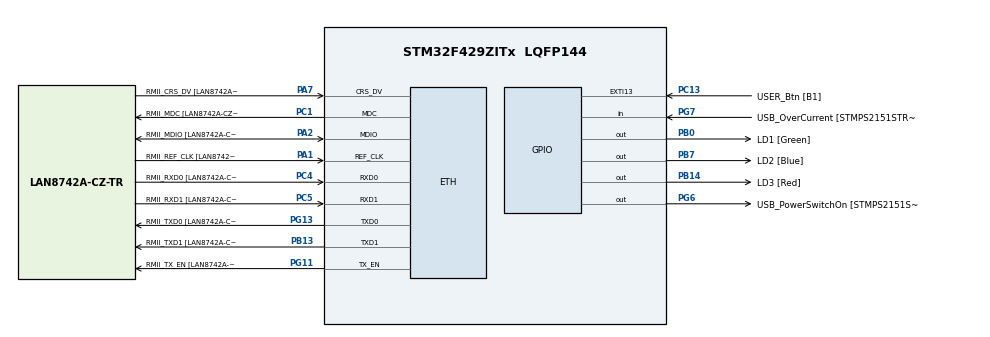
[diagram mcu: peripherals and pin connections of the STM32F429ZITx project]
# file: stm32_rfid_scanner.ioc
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ETH.MediaInterface=HAL_ETH_RMII_MODE
ETH.PHY_Name=LAN8742A_PHY_ADDRESS
ETH.PHY_Value=0
ETH.PhyAddress=0
FREERTOS.Tasks01=defaultTask,0,512,StartDefaultTask,Default,NULL,Dynamic,NULL,NULL;sslTask,0,2560,StartSSLClientTask,As weak,NULL,Dynamic,NULL,NULL;lwipTask,-3,512,handleClientTask,Default,NULL,Dynamic,NULL,NULL
LWIP.BSP.number=1
LWIP.Version=v2.1.2_Cube
LWIP0.BSP.STBoard=false
LWIP0.BSP.api=BSP_COMPONENT_DRIVER
LWIP0.BSP.component=LAN8742
LWIP0.BSP.instance=LAN8742
LWIP0.BSP.name=Driver_PHY
LWIP0.BSP.semaphore=S_LAN8742
LWIP0.BSP.solution=LAN8742
Mcu.Family=STM32F4
Mcu.Name=STM32F429ZITx
Mcu.Package=LQFP144
NVIC.ETH_IRQn=true\:5\:0\:false\:false\:true\:true\:false\:true\:true
NVIC.EXTI15_10_IRQn=true\:5\:0\:false\:false\:true\:true\:true\:true\:true
NVIC.PriorityGroup=NVIC_PRIORITYGROUP_4
PA1.GPIO_Label=RMII_REF_CLK [LAN8742A-CZ-TR_REFCLK0]
PA1.Mode=RMII
PA1.Signal=ETH_REF_CLK
PA10.GPIO_Label=USB_ID
PA10.Signal=USB_OTG_FS_ID
PA11.GPIO_Label=USB_DM
PA11.Signal=USB_OTG_FS_DM
PA12.GPIO_Label=USB_DP
PA12.Signal=USB_OTG_FS_DP
PA13.GPIO_Label=TMS
PA13.Mode=Serial_Wire
PA13.Signal=SYS_JTMS-SWDIO
PA14.GPIO_Label=TCK
PA14.Mode=Serial_Wire
PA14.Signal=SYS_JTCK-SWCLK
PA2.GPIO_Label=RMII_MDIO [LAN8742A-CZ-TR_MDIO]
PA2.Mode=RMII
PA2.Signal=ETH_MDIO
PA7.GPIO_Label=RMII_CRS_DV [LAN8742A-CZ-TR_CRS_DV]
PA7.Mode=RMII
PA7.Signal=ETH_CRS_DV
PA8.GPIO_Label=USB_SOF [TP1]
PA8.Signal=USB_OTG_FS_SOF
PA9.GPIO_Label=USB_VBUS
PA9.Signal=USB_OTG_FS_VBUS
PB0.GPIO_Label=LD1 [Green]
PB0.Signal=GPIO_Output
PB13.GPIO_Label=RMII_TXD1 [LAN8742A-CZ-TR_TXD1]
PB13.Mode=RMII
PB13.Signal=ETH_TXD1
PB14.GPIO_Label=LD3 [Red]
PB14.Signal=GPIO_Output
PB7.GPIO_Label=LD2 [Blue]
PB7.Signal=GPIO_Output
PC1.GPIO_Label=RMII_MDC [LAN8742A-CZ-TR_MDC]
PC1.Mode=RMII
PC1.Signal=ETH_MDC
PC13.GPIO_Label=USER_Btn [B1]
PC13.Signal=GPXTI13
PC14/OSC32_IN.Mode=LSE-External-Oscillator
PC14/OSC32_IN.Signal=RCC_OSC32_IN
PC15/OSC32_OUT.Mode=LSE-External-Oscillator
PC15/OSC32_OUT.Signal=RCC_OSC32_OUT
PC4.GPIO_Label=RMII_RXD0 [LAN8742A-CZ-TR_RXD0]
PC4.Mode=RMII
PC4.Signal=ETH_RXD0
PC5.GPIO_Label=RMII_RXD1 [LAN8742A-CZ-TR_RXD1]
PC5.Mode=RMII
PC5.Signal=ETH_RXD1
PD8.GPIO_Label=STLK_RX [STM32F103CBT6_PA3]
PD8.Signal=USART3_TX
PD9.GPIO_Label=STLK_TX [STM32F103CBT6_PA2]
PD9.Signal=USART3_RX
PG11.GPIO_Label=RMII_TX_EN [LAN8742A-CZ-TR_TXEN]
PG11.Mode=RMII
PG11.Signal=ETH_TX_EN
PG13.GPIO_Label=RMII_TXD0 [LAN8742A-CZ-TR_TXD0]
PG13.Mode=RMII
PG13.Signal=ETH_TXD0
PG6.GPIO_Label=USB_PowerSwitchOn [STMPS2151STR_EN]
PG6.Signal=GPIO_Output
PG7.GPIO_Label=USB_OverCurrent [STMPS2151STR_FAULT]
PG7.Signal=GPIO_Input
PH0/OSC_IN.Mode=HSE-External-Clock-Source
PH0/OSC_IN.Signal=RCC_OSC_IN
PH1/OSC_OUT.Mode=HSE-External-Clock-Source
PH1/OSC_OUT.Signal=RCC_OSC_OUT
ProjectManager.HeapSize=0x200
ProjectManager.StackSize=0x400
ProjectManager.TargetToolchain=STM32CubeIDE
VP_FREERTOS_VS_CMSIS_V1.Mode=CMSIS_V1
VP_LWIP_VS_Enabled.Mode=Enabled
VP_RNG_VS_RNG.Mode=RNG_Activate
board=NUCLEO-F429ZI

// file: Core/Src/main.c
/* USER CODE BEGIN Header */
/**
  ******************************************************************************
  * @file           : main.c
  * @brief          : Main program body
  ******************************************************************************
  * @attention
  *
  * Copyright (c) 2023 STMicroelectronics.
  * All rights reserved.
  *
  * This software is licensed under terms that can be found in the LICENSE file
  * in the root directory of this software component.
  * If no LICENSE file comes with this software, it is provided AS-IS.
  *
  ******************************************************************************
  */
/* USER CODE END Header */
#include "main.h"
#include "cmsis_os.h"
#include "lwip.h"

/* USER CODE BEGIN Includes */
#include "iot_connect.h"
#include "SEGGER_RTT.h"
/* USER CODE END Includes */

RNG_HandleTypeDef hrng;

osThreadId defaultTaskHandle;
//osThreadId sslTaskHandle;
//osThreadId lwipTaskHandle;

void SystemClock_Config(void);
static void MX_GPIO_Init(void);
static void MX_RNG_Init(void);
void StartDefaultTask(void const * argument);
//void StartSSLClientTask(void const * argument);
//void handleClientTask(void const * argument);

int main(void)
{
  /* USER CODE BEGIN 1 */
	SEGGER_RTT_printf(0, "Application start\r\n");
  /* USER CODE END 1 */

  /* MCU Configuration--------------------------------------------------------*/

  /* Reset of all peripherals, Initializes the Flash interface and the Systick. */
  HAL_Init();

  /* Configure the system clock */
  SystemClock_Config();

  /* Initialize all configured peripherals */
  MX_GPIO_Init();
  MX_RNG_Init();
  SEGGER_RTT_printf(0, "q\r\n");

  /* Create the thread(s) */
  /* definition and creation of defaultTask */
  osThreadDef(defaultTask, StartDefaultTask, osPriorityNormal, 0, 512);
  SEGGER_RTT_printf(0, "b\r\n");
  defaultTaskHandle = osThreadCreate(osThread(defaultTask), NULL);
  SEGGER_RTT_printf(0, "a\r\n");

//  /* definition and creation of sslTask */
//  osThreadDef(sslTask, StartSSLClientTask, osPriorityNormal, 0, 2560);
//  sslTaskHandle = osThreadCreate(osThread(sslTask), NULL);

//  /* definition and creation of lwipTask */
//  osThreadDef(lwipTask, handleClientTask, osPriorityIdle, 0, 512);
//  lwipTaskHandle = osThreadCreate(osThread(lwipTask), NULL);

  /* Start scheduler */
  osKernelStart();
  SEGGER_RTT_printf(0, "c\r\n");

  /* We should never get here as control is now taken by the scheduler */
  /* Infinite loop */
  while (1)
  {

  }
}

void SystemClock_Config(void)
{
  RCC_OscInitTypeDef RCC_OscInitStruct = {0};
  RCC_ClkInitTypeDef RCC_ClkInitStruct = {0};

  /** Configure the main internal regulator output voltage
  */
  __HAL_RCC_PWR_CLK_ENABLE();
  __HAL_PWR_VOLTAGESCALING_CONFIG(PWR_REGULATOR_VOLTAGE_SCALE3);

  /** Initializes the RCC Oscillators according to the specified parameters
  * in the RCC_OscInitTypeDef structure.
  */
  RCC_OscInitStruct.OscillatorType = RCC_OSCILLATORTYPE_HSI;
  RCC_OscInitStruct.HSIState = RCC_HSI_ON;
  RCC_OscInitStruct.HSICalibrationValue = RCC_HSICALIBRATION_DEFAULT;
  RCC_OscInitStruct.PLL.PLLState = RCC_PLL_ON;
  RCC_OscInitStruct.PLL.PLLSource = RCC_PLLSOURCE_HSI;
  RCC_OscInitStruct.PLL.PLLM = 16;
  RCC_OscInitStruct.PLL.PLLN = 192;
  RCC_OscInitStruct.PLL.PLLP = RCC_PLLP_DIV2;
  RCC_OscInitStruct.PLL.PLLQ = 4;
  if (HAL_RCC_OscConfig(&RCC_OscInitStruct) != HAL_OK)
  {
    Error_Handler();
  }

  /** Initializes the CPU, AHB and APB buses clocks
  */
  RCC_ClkInitStruct.ClockType = RCC_CLOCKTYPE_HCLK|RCC_CLOCKTYPE_SYSCLK
                              |RCC_CLOCKTYPE_PCLK1|RCC_CLOCKTYPE_PCLK2;
  RCC_ClkInitStruct.SYSCLKSource = RCC_SYSCLKSOURCE_HSI;
  RCC_ClkInitStruct.AHBCLKDivider = RCC_SYSCLK_DIV1;
  RCC_ClkInitStruct.APB1CLKDivider = RCC_HCLK_DIV1;
  RCC_ClkInitStruct.APB2CLKDivider = RCC_HCLK_DIV1;

  if (HAL_RCC_ClockConfig(&RCC_ClkInitStruct, FLASH_LATENCY_0) != HAL_OK)
  {
    Error_Handler();
  }
}

static void MX_RNG_Init(void)
{

  hrng.Instance = RNG;
  if (HAL_RNG_Init(&hrng) != HAL_OK)
  {
    Error_Handler();
  }

}

static void MX_GPIO_Init(void)
{
  GPIO_InitTypeDef GPIO_InitStruct = {0};

  /* GPIO Ports Clock Enable */
  __HAL_RCC_GPIOC_CLK_ENABLE();
  __HAL_RCC_GPIOH_CLK_ENABLE();
  __HAL_RCC_GPIOA_CLK_ENABLE();
  __HAL_RCC_GPIOB_CLK_ENABLE();
  __HAL_RCC_GPIOD_CLK_ENABLE();
  __HAL_RCC_GPIOG_CLK_ENABLE();

  /*Configure GPIO pin Output Level */
  HAL_GPIO_WritePin(GPIOB, LD1_Pin|LD3_Pin|LD2_Pin, GPIO_PIN_RESET);

  /*Configure GPIO pin Output Level */
  HAL_GPIO_WritePin(USB_PowerSwitchOn_GPIO_Port, USB_PowerSwitchOn_Pin, GPIO_PIN_RESET);

  /*Configure GPIO pin : USER_Btn_Pin */
  GPIO_InitStruct.Pin = USER_Btn_Pin;
  GPIO_InitStruct.Mode = GPIO_MODE_IT_RISING;
  GPIO_InitStruct.Pull = GPIO_NOPULL;
  HAL_GPIO_Init(USER_Btn_GPIO_Port, &GPIO_InitStruct);

  /*Configure GPIO pins : LD1_Pin LD3_Pin LD2_Pin */
  GPIO_InitStruct.Pin = LD1_Pin|LD3_Pin|LD2_Pin;
  GPIO_InitStruct.Mode = GPIO_MODE_OUTPUT_PP;
  GPIO_InitStruct.Pull = GPIO_NOPULL;
  GPIO_InitStruct.Speed = GPIO_SPEED_FREQ_LOW;
  HAL_GPIO_Init(GPIOB, &GPIO_InitStruct);

  /*Configure GPIO pins : STLK_RX_Pin STLK_TX_Pin */
  GPIO_InitStruct.Pin = STLK_RX_Pin|STLK_TX_Pin;
  GPIO_InitStruct.Mode = GPIO_MODE_AF_PP;
  GPIO_InitStruct.Pull = GPIO_NOPULL;
  GPIO_InitStruct.Speed = GPIO_SPEED_FREQ_VERY_HIGH;
  GPIO_InitStruct.Alternate = GPIO_AF7_USART3;
  HAL_GPIO_Init(GPIOD, &GPIO_InitStruct);

  /*Configure GPIO pin : USB_PowerSwitchOn_Pin */
  GPIO_InitStruct.Pin = USB_PowerSwitchOn_Pin;
  GPIO_InitStruct.Mode = GPIO_MODE_OUTPUT_PP;
  GPIO_InitStruct.Pull = GPIO_NOPULL;
  GPIO_InitStruct.Speed = GPIO_SPEED_FREQ_LOW;
  HAL_GPIO_Init(USB_PowerSwitchOn_GPIO_Port, &GPIO_InitStruct);

  /*Configure GPIO pin : USB_OverCurrent_Pin */
  GPIO_InitStruct.Pin = USB_OverCurrent_Pin;
  GPIO_InitStruct.Mode = GPIO_MODE_INPUT;
  GPIO_InitStruct.Pull = GPIO_NOPULL;
  HAL_GPIO_Init(USB_OverCurrent_GPIO_Port, &GPIO_InitStruct);

  /*Configure GPIO pins : USB_SOF_Pin USB_ID_Pin USB_DM_Pin USB_DP_Pin */
  GPIO_InitStruct.Pin = USB_SOF_Pin|USB_ID_Pin|USB_DM_Pin|USB_DP_Pin;
  GPIO_InitStruct.Mode = GPIO_MODE_AF_PP;
  GPIO_InitStruct.Pull = GPIO_NOPULL;
  GPIO_InitStruct.Speed = GPIO_SPEED_FREQ_VERY_HIGH;
  GPIO_InitStruct.Alternate = GPIO_AF10_OTG_FS;
  HAL_GPIO_Init(GPIOA, &GPIO_InitStruct);

  /*Configure GPIO pin : USB_VBUS_Pin */
  GPIO_InitStruct.Pin = USB_VBUS_Pin;
  GPIO_InitStruct.Mode = GPIO_MODE_INPUT;
  GPIO_InitStruct.Pull = GPIO_NOPULL;
  HAL_GPIO_Init(USB_VBUS_GPIO_Port, &GPIO_InitStruct);

  /* EXTI interrupt init*/
  HAL_NVIC_SetPriority(EXTI15_10_IRQn, 5, 0);
  HAL_NVIC_EnableIRQ(EXTI15_10_IRQn);

}

///* USER CODE BEGIN Header_StartSSLClientTask */
///**
//* @brief Function implementing the sslTask thread.
//* @param argument: Not used
//* @retval None
//*/
///* USER CODE END Header_StartSSLClientTask */
//__weak void StartSSLClientTask(void const * argument)
//{
//  /* USER CODE BEGIN StartSSLClientTask */
//  /* Infinite loop */
//  for(;;)
//  {
//    osDelay(1);
//  }
//  /* USER CODE END StartSSLClientTask */
//}
//
///* USER CODE BEGIN Header_handleClientTask */
///**
//* @brief Function implementing the lwipTask thread.
//* @param argument: Not used
//* @retval None
//*/
///* USER CODE END Header_handleClientTask */
//void handleClientTask(void const * argument)
//{
//  /* USER CODE BEGIN handleClientTask */
//  /* Infinite loop */
//  for(;;)
//  {
//    osDelay(1);
//  }
//  /* USER CODE END handleClientTask */
//}

void Error_Handler(void)
{
  __disable_irq();
  while (1)
  {
  }
}

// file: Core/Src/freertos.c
/* USER CODE BEGIN Header */
/**
  ******************************************************************************
  * File Name          : freertos.c
  * Description        : Code for freertos applications
  ******************************************************************************
  * @attention
  *
  * Copyright (c) 2023 STMicroelectronics.
  * All rights reserved.
  *
  * This software is licensed under terms that can be found in the LICENSE file
  * in the root directory of this software component.
  * If no LICENSE file comes with this software, it is provided AS-IS.
  *
  ******************************************************************************
  */
/* USER CODE END Header */

#include "FreeRTOS.h"
#include "task.h"
#include "main.h"
#include "iot_connect.h"

/* GetIdleTaskMemory prototype (linked to static allocation support) */
void vApplicationGetIdleTaskMemory( StaticTask_t **ppxIdleTaskTCBBuffer, StackType_t **ppxIdleTaskStackBuffer, uint32_t *pulIdleTaskStackSize );

/* USER CODE BEGIN GET_IDLE_TASK_MEMORY */
static StaticTask_t xIdleTaskTCBBuffer;
static StackType_t xIdleStack[configMINIMAL_STACK_SIZE];
char * SubString(const char * source, int i, int j);
void vApplicationGetIdleTaskMemory( StaticTask_t **ppxIdleTaskTCBBuffer, StackType_t **ppxIdleTaskStackBuffer, uint32_t *pulIdleTaskStackSize )
{
  *ppxIdleTaskTCBBuffer = &xIdleTaskTCBBuffer;
  *ppxIdleTaskStackBuffer = &xIdleStack[0];
  *pulIdleTaskStackSize = configMINIMAL_STACK_SIZE;
  /* place for user code */
}
/* USER CODE END GET_IDLE_TASK_MEMORY */

/* USER CODE END handleClientTask */
/* USER CODE BEGIN Application */
char * SubString(const char * source, int i, int j)
{
	int source_len = strlen(source);
	if (j >= source_len - 1) j = source_len - 1;
	int sub_len = j - i + 1;
	char * sub_string = (char * )malloc((sub_len + 1) * sizeof(char));
	if (sub_string == NULL)
	{
		return NULL;
	}
	for (int k = i; k <= j; k++)
	{
		sub_string[k-i] = source[k];
	}
	sub_string[j-i] = '\0';
	return sub_string;
}
/* USER CODE END Application */
